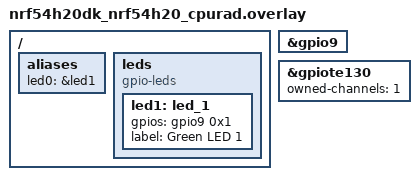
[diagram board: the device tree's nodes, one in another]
/*
 * Copyright (c) 2024 Nordic Semiconductor ASA
 *
 * SPDX-License-Identifier: LicenseRef-Nordic-5-Clause
 */

/ {
	aliases {
		led0 = &led1;
	};

	leds {
		compatible = "gpio-leds";

		led1: led_1 {
			gpios = <&gpio9 0x1 0x0>;
			label = "Green LED 1";
		};
	};
};

&gpio9 {
	status = "okay";
};

&gpiote130 {
	status = "okay";
	owned-channels = <1>;
};
